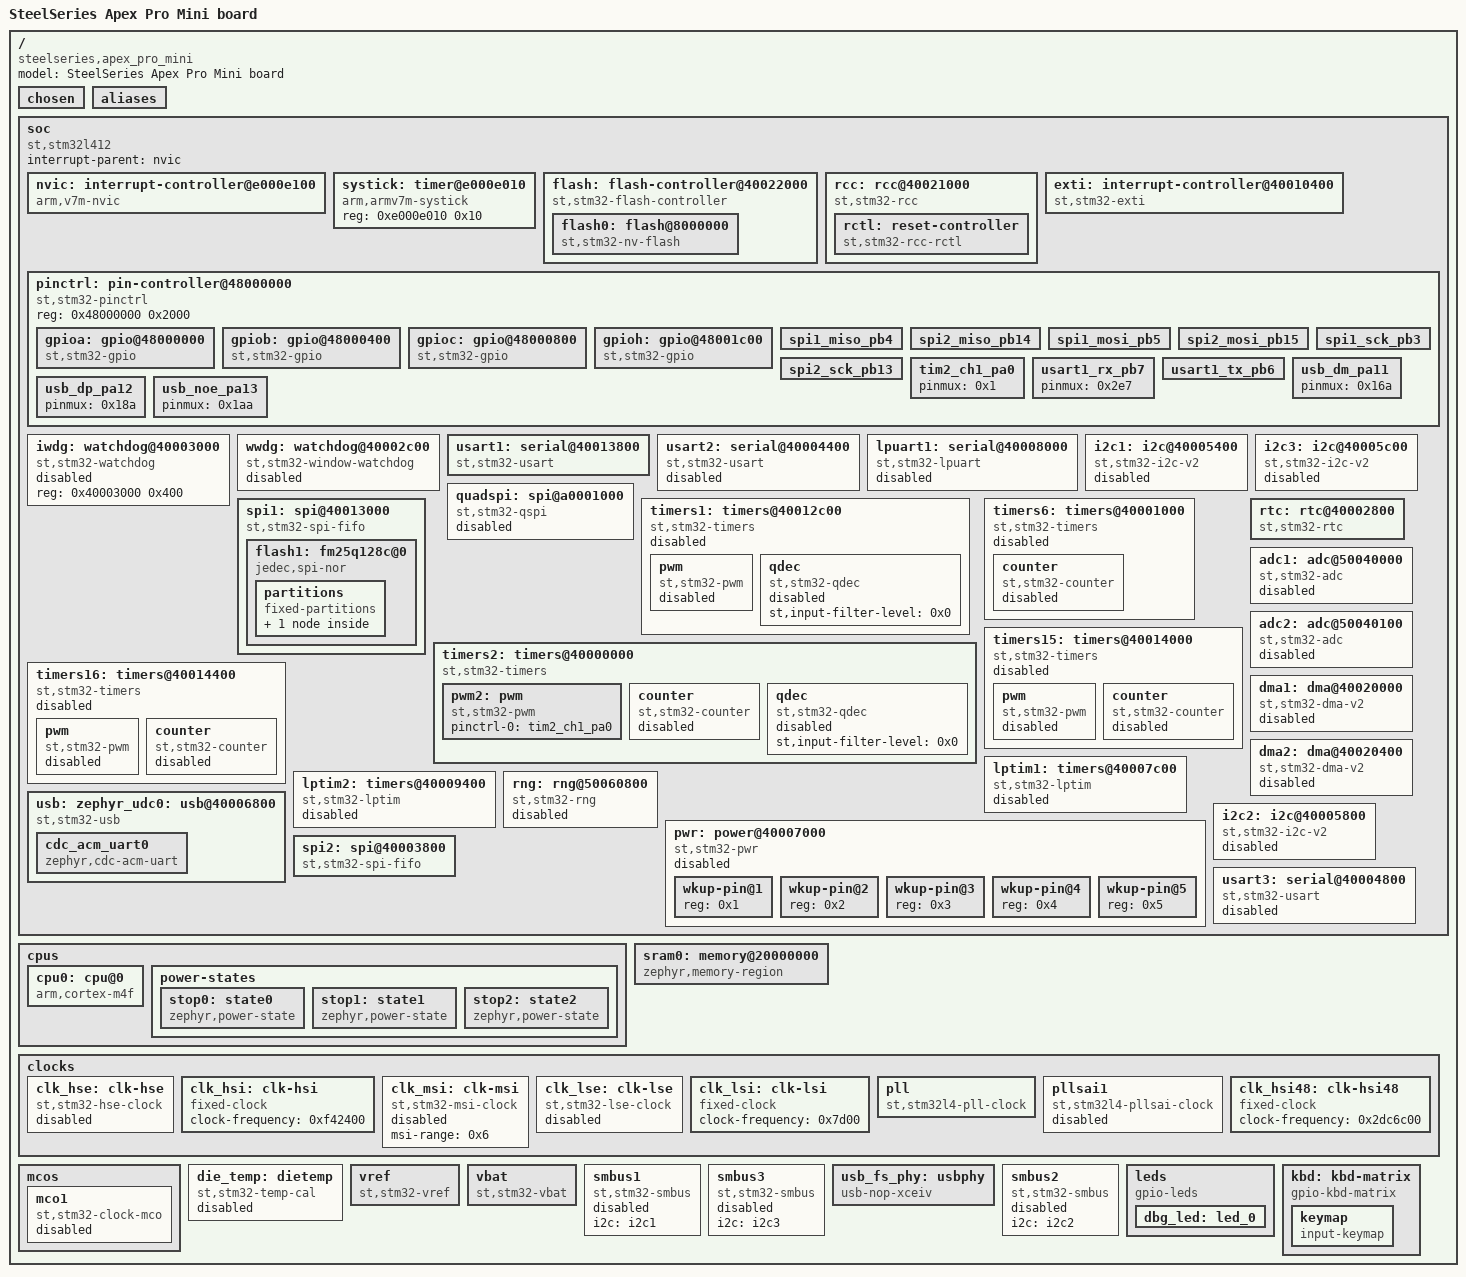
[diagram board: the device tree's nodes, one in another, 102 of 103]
/dts-v1/;

/* node '/' defined in zephyr/dts/common/skeleton.dtsi:9 */
/ {
	#address-cells = < 0x1 >;                  /* in zephyr/dts/common/skeleton.dtsi:10 */
	#size-cells = < 0x1 >;                     /* in zephyr/dts/common/skeleton.dtsi:11 */
	model = "SteelSeries Apex Pro Mini board"; /* in zephyr/boards/steelseries/apex_pro_mini/apex_pro_mini.dts:14 */
	compatible = "steelseries,apex_pro_mini",
	             "st,stm32l412";               /* in zephyr/boards/steelseries/apex_pro_mini/apex_pro_mini.dts:15 */

	/* node '/chosen' defined in zephyr/dts/common/skeleton.dtsi:13 */
	chosen {
		zephyr,entropy = &rng;              /* in zephyr/dts/arm/st/l4/stm32l4.dtsi:26 */
		zephyr,flash-controller = &flash;   /* in zephyr/dts/arm/st/l4/stm32l4.dtsi:27 */
		zephyr,console = &cdc_acm_uart0;    /* in zephyr/boards/steelseries/apex_pro_mini/apex_pro_mini.dts:18 */
		zephyr,shell-uart = &cdc_acm_uart0; /* in zephyr/boards/steelseries/apex_pro_mini/apex_pro_mini.dts:19 */
		zephyr,sram = &sram0;               /* in zephyr/boards/steelseries/apex_pro_mini/apex_pro_mini.dts:20 */
		zephyr,flash = &flash0;             /* in zephyr/boards/steelseries/apex_pro_mini/apex_pro_mini.dts:21 */
	};

	/* node '/aliases' defined in zephyr/dts/common/skeleton.dtsi:15 */
	aliases {
		led0 = &dbg_led;      /* in zephyr/boards/steelseries/apex_pro_mini/apex_pro_mini.dts:34 */
		volt-sensor0 = &vref; /* in zephyr/boards/steelseries/apex_pro_mini/apex_pro_mini.dts:35 */
		volt-sensor1 = &vbat; /* in zephyr/boards/steelseries/apex_pro_mini/apex_pro_mini.dts:36 */
	};

	/* node '/soc' defined in zephyr/dts/arm/armv7-m.dtsi:6 */
	soc {
		#address-cells = < 0x1 >;     /* in zephyr/dts/arm/armv7-m.dtsi:7 */
		#size-cells = < 0x1 >;        /* in zephyr/dts/arm/armv7-m.dtsi:8 */
		interrupt-parent = < &nvic >; /* in zephyr/dts/arm/armv7-m.dtsi:10 */
		ranges;                       /* in zephyr/dts/arm/armv7-m.dtsi:11 */
		compatible = "st,stm32l412",
		             "st,stm32l4",
		             "simple-bus";    /* in zephyr/dts/arm/st/l4/stm32l412.dtsi:20 */

		/* node '/soc/interrupt-controller@e000e100' defined in zephyr/dts/arm/armv7-m.dtsi:13 */
		nvic: interrupt-controller@e000e100 {
			#address-cells = < 0x1 >;            /* in zephyr/dts/arm/armv7-m.dtsi:14 */
			compatible = "arm,v7m-nvic";         /* in zephyr/dts/arm/armv7-m.dtsi:15 */
			reg = < 0xe000e100 0xc00 >;          /* in zephyr/dts/arm/armv7-m.dtsi:16 */
			interrupt-controller;                /* in zephyr/dts/arm/armv7-m.dtsi:17 */
			#interrupt-cells = < 0x2 >;          /* in zephyr/dts/arm/armv7-m.dtsi:18 */
			arm,num-irq-priority-bits = < 0x4 >; /* in zephyr/dts/arm/st/l4/stm32l4.dtsi:596 */
			phandle = < 0x1 >;                   /* in zephyr/dts/arm/armv7-m.dtsi:10 */
		};

		/* node '/soc/timer@e000e010' defined in zephyr/dts/arm/armv7-m.dtsi:21 */
		systick: timer@e000e010 {
			compatible = "arm,armv7m-systick"; /* in zephyr/dts/arm/armv7-m.dtsi:22 */
			reg = < 0xe000e010 0x10 >;         /* in zephyr/dts/arm/armv7-m.dtsi:23 */
		};

		/* node '/soc/flash-controller@40022000' defined in zephyr/dts/arm/st/l4/stm32l4.dtsi:127 */
		flash: flash-controller@40022000 {
			compatible = "st,stm32-flash-controller",
			             "st,stm32l4-flash-controller"; /* in zephyr/dts/arm/st/l4/stm32l4.dtsi:128 */
			reg = < 0x40022000 0x400 >;                 /* in zephyr/dts/arm/st/l4/stm32l4.dtsi:129 */
			interrupts = < 0x4 0x0 >;                   /* in zephyr/dts/arm/st/l4/stm32l4.dtsi:130 */
			clocks = < &rcc 0x48 0x100 >;               /* in zephyr/dts/arm/st/l4/stm32l4.dtsi:131 */
			#address-cells = < 0x1 >;                   /* in zephyr/dts/arm/st/l4/stm32l4.dtsi:133 */
			#size-cells = < 0x1 >;                      /* in zephyr/dts/arm/st/l4/stm32l4.dtsi:134 */

			/* node '/soc/flash-controller@40022000/flash@8000000' defined in zephyr/dts/arm/st/l4/stm32l4.dtsi:136 */
			flash0: flash@8000000 {
				compatible = "st,stm32-nv-flash",
				             "soc-nv-flash";      /* in zephyr/dts/arm/st/l4/stm32l4.dtsi:137 */
				write-block-size = < 0x8 >;       /* in zephyr/dts/arm/st/l4/stm32l4.dtsi:139 */
				erase-block-size = < 0x800 >;     /* in zephyr/dts/arm/st/l4/stm32l4.dtsi:140 */
				max-erase-time = < 0x19 >;        /* in zephyr/dts/arm/st/l4/stm32l4.dtsi:142 */
				reg = < 0x8000000 0x20000 >;      /* in zephyr/dts/arm/st/l4/stm32l412XB.dtsi:17 */
			};
		};

		/* node '/soc/rcc@40021000' defined in zephyr/dts/arm/st/l4/stm32l4.dtsi:146 */
		rcc: rcc@40021000 {
			compatible = "st,stm32-rcc";     /* in zephyr/dts/arm/st/l4/stm32l4.dtsi:147 */
			#clock-cells = < 0x2 >;          /* in zephyr/dts/arm/st/l4/stm32l4.dtsi:148 */
			reg = < 0x40021000 0x400 >;      /* in zephyr/dts/arm/st/l4/stm32l4.dtsi:149 */
			clocks = < &pll >;               /* in zephyr/boards/steelseries/apex_pro_mini/apex_pro_mini.dts:160 */
			clock-frequency = < 0x4c4b400 >; /* in zephyr/boards/steelseries/apex_pro_mini/apex_pro_mini.dts:161 */
			ahb-prescaler = < 0x1 >;         /* in zephyr/boards/steelseries/apex_pro_mini/apex_pro_mini.dts:162 */
			apb1-prescaler = < 0x1 >;        /* in zephyr/boards/steelseries/apex_pro_mini/apex_pro_mini.dts:163 */
			apb2-prescaler = < 0x1 >;        /* in zephyr/boards/steelseries/apex_pro_mini/apex_pro_mini.dts:164 */
			phandle = < 0x2 >;               /* in zephyr/dts/arm/st/l4/stm32l4.dtsi:131 */

			/* node '/soc/rcc@40021000/reset-controller' defined in zephyr/dts/arm/st/l4/stm32l4.dtsi:151 */
			rctl: reset-controller {
				compatible = "st,stm32-rcc-rctl"; /* in zephyr/dts/arm/st/l4/stm32l4.dtsi:152 */
				#reset-cells = < 0x1 >;           /* in zephyr/dts/arm/st/l4/stm32l4.dtsi:153 */
				phandle = < 0x4 >;                /* in zephyr/dts/arm/st/l4/stm32l4.dtsi:230 */
			};
		};

		/* node '/soc/interrupt-controller@40010400' defined in zephyr/dts/arm/st/l4/stm32l4.dtsi:157 */
		exti: interrupt-controller@40010400 {
			compatible = "st,stm32-exti";  /* in zephyr/dts/arm/st/l4/stm32l4.dtsi:158 */
			interrupt-controller;          /* in zephyr/dts/arm/st/l4/stm32l4.dtsi:159 */
			#interrupt-cells = < 0x1 >;    /* in zephyr/dts/arm/st/l4/stm32l4.dtsi:160 */
			#address-cells = < 0x0 >;      /* in zephyr/dts/arm/st/l4/stm32l4.dtsi:161 */
			reg = < 0x40010400 0x400 >;    /* in zephyr/dts/arm/st/l4/stm32l4.dtsi:162 */
			clocks = < &rcc 0x60 0x1 >;    /* in zephyr/dts/arm/st/l4/stm32l4.dtsi:163 */
			num-lines = < 0x40 >;          /* in zephyr/dts/arm/st/l4/stm32l4.dtsi:164 */
			interrupts = < 0x6 0x0 >,
			             < 0x7 0x0 >,
			             < 0x8 0x0 >,
			             < 0x9 0x0 >,
			             < 0xa 0x0 >,
			             < 0x17 0x0 >,
			             < 0x28 0x0 >;     /* in zephyr/dts/arm/st/l4/stm32l4.dtsi:165 */
			interrupt-names = "line0",
			                  "line1",
			                  "line2",
			                  "line3",
			                  "line4",
			                  "line5-9",
			                  "line10-15"; /* in zephyr/dts/arm/st/l4/stm32l4.dtsi:167 */
			line-ranges = < 0x0 0x1 >,
			              < 0x1 0x1 >,
			              < 0x2 0x1 >,
			              < 0x3 0x1 >,
			              < 0x4 0x1 >,
			              < 0x5 0x5 >,
			              < 0xa 0x6 >;     /* in zephyr/dts/arm/st/l4/stm32l4.dtsi:169 */
		};

		/* node '/soc/pin-controller@48000000' defined in zephyr/dts/arm/st/l4/stm32l4.dtsi:173 */
		pinctrl: pin-controller@48000000 {
			compatible = "st,stm32-pinctrl"; /* in zephyr/dts/arm/st/l4/stm32l4.dtsi:174 */
			#address-cells = < 0x1 >;        /* in zephyr/dts/arm/st/l4/stm32l4.dtsi:175 */
			#size-cells = < 0x1 >;           /* in zephyr/dts/arm/st/l4/stm32l4.dtsi:176 */
			reg = < 0x48000000 0x2000 >;     /* in zephyr/dts/arm/st/l4/stm32l4.dtsi:177 */

			/* node '/soc/pin-controller@48000000/gpio@48000000' defined in zephyr/dts/arm/st/l4/stm32l4.dtsi:179 */
			gpioa: gpio@48000000 {
				compatible = "st,stm32-gpio"; /* in zephyr/dts/arm/st/l4/stm32l4.dtsi:180 */
				gpio-controller;              /* in zephyr/dts/arm/st/l4/stm32l4.dtsi:181 */
				#gpio-cells = < 0x2 >;        /* in zephyr/dts/arm/st/l4/stm32l4.dtsi:182 */
				reg = < 0x48000000 0x400 >;   /* in zephyr/dts/arm/st/l4/stm32l4.dtsi:183 */
				clocks = < &rcc 0x4c 0x1 >;   /* in zephyr/dts/arm/st/l4/stm32l4.dtsi:184 */
				phandle = < 0xa >;            /* in zephyr/boards/steelseries/apex_pro_mini/apex_pro_mini.dts:177 */
			};

			/* node '/soc/pin-controller@48000000/gpio@48000400' defined in zephyr/dts/arm/st/l4/stm32l4.dtsi:187 */
			gpiob: gpio@48000400 {
				compatible = "st,stm32-gpio"; /* in zephyr/dts/arm/st/l4/stm32l4.dtsi:188 */
				gpio-controller;              /* in zephyr/dts/arm/st/l4/stm32l4.dtsi:189 */
				#gpio-cells = < 0x2 >;        /* in zephyr/dts/arm/st/l4/stm32l4.dtsi:190 */
				reg = < 0x48000400 0x400 >;   /* in zephyr/dts/arm/st/l4/stm32l4.dtsi:191 */
				clocks = < &rcc 0x4c 0x2 >;   /* in zephyr/dts/arm/st/l4/stm32l4.dtsi:192 */
				phandle = < 0x13 >;           /* in zephyr/boards/steelseries/apex_pro_mini/apex_pro_mini.dts:193 */
			};

			/* node '/soc/pin-controller@48000000/gpio@48000800' defined in zephyr/dts/arm/st/l4/stm32l4.dtsi:195 */
			gpioc: gpio@48000800 {
				compatible = "st,stm32-gpio"; /* in zephyr/dts/arm/st/l4/stm32l4.dtsi:196 */
				gpio-controller;              /* in zephyr/dts/arm/st/l4/stm32l4.dtsi:197 */
				#gpio-cells = < 0x2 >;        /* in zephyr/dts/arm/st/l4/stm32l4.dtsi:198 */
				reg = < 0x48000800 0x400 >;   /* in zephyr/dts/arm/st/l4/stm32l4.dtsi:199 */
				clocks = < &rcc 0x4c 0x4 >;   /* in zephyr/dts/arm/st/l4/stm32l4.dtsi:200 */
				phandle = < 0x1c >;           /* in zephyr/boards/steelseries/apex_pro_mini/apex_pro_mini.dts:28 */
			};

			/* node '/soc/pin-controller@48000000/gpio@48001c00' defined in zephyr/dts/arm/st/l4/stm32l4.dtsi:203 */
			gpioh: gpio@48001c00 {
				compatible = "st,stm32-gpio"; /* in zephyr/dts/arm/st/l4/stm32l4.dtsi:204 */
				gpio-controller;              /* in zephyr/dts/arm/st/l4/stm32l4.dtsi:205 */
				#gpio-cells = < 0x2 >;        /* in zephyr/dts/arm/st/l4/stm32l4.dtsi:206 */
				reg = < 0x48001c00 0x400 >;   /* in zephyr/dts/arm/st/l4/stm32l4.dtsi:207 */
				clocks = < &rcc 0x4c 0x80 >;  /* in zephyr/dts/arm/st/l4/stm32l4.dtsi:208 */
			};

			/* node '/soc/pin-controller@48000000/spi1_miso_pb4' defined in modules/hal/stm32/dts/st/l4/stm32l412rbtx-pinctrl.dtsi:613 */
			spi1_miso_pb4: spi1_miso_pb4 {
				pinmux = < 0x285 >; /* in modules/hal/stm32/dts/st/l4/stm32l412rbtx-pinctrl.dtsi:614 */
				bias-pull-down;     /* in modules/hal/stm32/dts/st/l4/stm32l412rbtx-pinctrl.dtsi:615 */
				phandle = < 0x8 >;  /* in zephyr/boards/steelseries/apex_pro_mini/apex_pro_mini.dts:175 */
			};

			/* node '/soc/pin-controller@48000000/spi2_miso_pb14' defined in modules/hal/stm32/dts/st/l4/stm32l412rbtx-pinctrl.dtsi:618 */
			spi2_miso_pb14: spi2_miso_pb14 {
				pinmux = < 0x3c5 >; /* in modules/hal/stm32/dts/st/l4/stm32l412rbtx-pinctrl.dtsi:619 */
				bias-pull-down;     /* in modules/hal/stm32/dts/st/l4/stm32l412rbtx-pinctrl.dtsi:620 */
				phandle = < 0x11 >; /* in zephyr/boards/steelseries/apex_pro_mini/apex_pro_mini.dts:191 */
			};

			/* node '/soc/pin-controller@48000000/spi1_mosi_pb5' defined in modules/hal/stm32/dts/st/l4/stm32l412rbtx-pinctrl.dtsi:640 */
			spi1_mosi_pb5: spi1_mosi_pb5 {
				pinmux = < 0x2a5 >; /* in modules/hal/stm32/dts/st/l4/stm32l412rbtx-pinctrl.dtsi:641 */
				bias-pull-down;     /* in modules/hal/stm32/dts/st/l4/stm32l412rbtx-pinctrl.dtsi:642 */
				phandle = < 0x9 >;  /* in zephyr/boards/steelseries/apex_pro_mini/apex_pro_mini.dts:175 */
			};

			/* node '/soc/pin-controller@48000000/spi2_mosi_pb15' defined in modules/hal/stm32/dts/st/l4/stm32l412rbtx-pinctrl.dtsi:645 */
			spi2_mosi_pb15: spi2_mosi_pb15 {
				pinmux = < 0x3e5 >; /* in modules/hal/stm32/dts/st/l4/stm32l412rbtx-pinctrl.dtsi:646 */
				bias-pull-down;     /* in modules/hal/stm32/dts/st/l4/stm32l412rbtx-pinctrl.dtsi:647 */
				phandle = < 0x12 >; /* in zephyr/boards/steelseries/apex_pro_mini/apex_pro_mini.dts:191 */
			};

			/* node '/soc/pin-controller@48000000/spi1_sck_pb3' defined in modules/hal/stm32/dts/st/l4/stm32l412rbtx-pinctrl.dtsi:696 */
			spi1_sck_pb3: spi1_sck_pb3 {
				pinmux = < 0x265 >;            /* in modules/hal/stm32/dts/st/l4/stm32l412rbtx-pinctrl.dtsi:697 */
				bias-pull-down;                /* in modules/hal/stm32/dts/st/l4/stm32l412rbtx-pinctrl.dtsi:698 */
				slew-rate = "very-high-speed"; /* in modules/hal/stm32/dts/st/l4/stm32l412rbtx-pinctrl.dtsi:699 */
				phandle = < 0x7 >;             /* in zephyr/boards/steelseries/apex_pro_mini/apex_pro_mini.dts:175 */
			};

			/* node '/soc/pin-controller@48000000/spi2_sck_pb13' defined in modules/hal/stm32/dts/st/l4/stm32l412rbtx-pinctrl.dtsi:708 */
			spi2_sck_pb13: spi2_sck_pb13 {
				pinmux = < 0x3a5 >;            /* in modules/hal/stm32/dts/st/l4/stm32l412rbtx-pinctrl.dtsi:709 */
				bias-pull-down;                /* in modules/hal/stm32/dts/st/l4/stm32l412rbtx-pinctrl.dtsi:710 */
				slew-rate = "very-high-speed"; /* in modules/hal/stm32/dts/st/l4/stm32l412rbtx-pinctrl.dtsi:711 */
				phandle = < 0x10 >;            /* in zephyr/boards/steelseries/apex_pro_mini/apex_pro_mini.dts:191 */
			};

			/* node '/soc/pin-controller@48000000/tim2_ch1_pa0' defined in modules/hal/stm32/dts/st/l4/stm32l412rbtx-pinctrl.dtsi:782 */
			tim2_ch1_pa0: tim2_ch1_pa0 {
				pinmux = < 0x1 >;  /* in modules/hal/stm32/dts/st/l4/stm32l412rbtx-pinctrl.dtsi:783 */
				phandle = < 0xb >; /* in zephyr/boards/steelseries/apex_pro_mini/apex_pro_mini.dts:202 */
			};

			/* node '/soc/pin-controller@48000000/usart1_rx_pb7' defined in modules/hal/stm32/dts/st/l4/stm32l412rbtx-pinctrl.dtsi:1069 */
			usart1_rx_pb7: usart1_rx_pb7 {
				pinmux = < 0x2e7 >; /* in modules/hal/stm32/dts/st/l4/stm32l412rbtx-pinctrl.dtsi:1070 */
				phandle = < 0x6 >;  /* in zephyr/boards/steelseries/apex_pro_mini/apex_pro_mini.dts:168 */
			};

			/* node '/soc/pin-controller@48000000/usart1_tx_pb6' defined in modules/hal/stm32/dts/st/l4/stm32l412rbtx-pinctrl.dtsi:1113 */
			usart1_tx_pb6: usart1_tx_pb6 {
				pinmux = < 0x2c7 >; /* in modules/hal/stm32/dts/st/l4/stm32l412rbtx-pinctrl.dtsi:1114 */
				bias-pull-up;       /* in modules/hal/stm32/dts/st/l4/stm32l412rbtx-pinctrl.dtsi:1115 */
				phandle = < 0x5 >;  /* in zephyr/boards/steelseries/apex_pro_mini/apex_pro_mini.dts:168 */
			};

			/* node '/soc/pin-controller@48000000/usb_dm_pa11' defined in modules/hal/stm32/dts/st/l4/stm32l412rbtx-pinctrl.dtsi:1150 */
			usb_dm_pa11: usb_dm_pa11 {
				pinmux = < 0x16a >; /* in modules/hal/stm32/dts/st/l4/stm32l412rbtx-pinctrl.dtsi:1151 */
				phandle = < 0xd >;  /* in zephyr/boards/steelseries/apex_pro_mini/apex_pro_mini.dts:232 */
			};

			/* node '/soc/pin-controller@48000000/usb_dp_pa12' defined in modules/hal/stm32/dts/st/l4/stm32l412rbtx-pinctrl.dtsi:1154 */
			usb_dp_pa12: usb_dp_pa12 {
				pinmux = < 0x18a >; /* in modules/hal/stm32/dts/st/l4/stm32l412rbtx-pinctrl.dtsi:1155 */
				phandle = < 0xe >;  /* in zephyr/boards/steelseries/apex_pro_mini/apex_pro_mini.dts:232 */
			};

			/* node '/soc/pin-controller@48000000/usb_noe_pa13' defined in modules/hal/stm32/dts/st/l4/stm32l412rbtx-pinctrl.dtsi:1158 */
			usb_noe_pa13: usb_noe_pa13 {
				pinmux = < 0x1aa >; /* in modules/hal/stm32/dts/st/l4/stm32l412rbtx-pinctrl.dtsi:1159 */
				phandle = < 0xf >;  /* in zephyr/boards/steelseries/apex_pro_mini/apex_pro_mini.dts:232 */
			};
		};

		/* node '/soc/watchdog@40003000' defined in zephyr/dts/arm/st/l4/stm32l4.dtsi:212 */
		iwdg: watchdog@40003000 {
			compatible = "st,stm32-watchdog"; /* in zephyr/dts/arm/st/l4/stm32l4.dtsi:213 */
			reg = < 0x40003000 0x400 >;       /* in zephyr/dts/arm/st/l4/stm32l4.dtsi:214 */
			status = "disabled";              /* in zephyr/dts/arm/st/l4/stm32l4.dtsi:215 */
		};

		/* node '/soc/watchdog@40002c00' defined in zephyr/dts/arm/st/l4/stm32l4.dtsi:218 */
		wwdg: watchdog@40002c00 {
			compatible = "st,stm32-window-watchdog"; /* in zephyr/dts/arm/st/l4/stm32l4.dtsi:219 */
			reg = < 0x40002c00 0x400 >;              /* in zephyr/dts/arm/st/l4/stm32l4.dtsi:220 */
			clocks = < &rcc 0x58 0x800 >;            /* in zephyr/dts/arm/st/l4/stm32l4.dtsi:221 */
			interrupts = < 0x0 0x7 >;                /* in zephyr/dts/arm/st/l4/stm32l4.dtsi:222 */
			status = "disabled";                     /* in zephyr/dts/arm/st/l4/stm32l4.dtsi:223 */
		};

		/* node '/soc/serial@40013800' defined in zephyr/dts/arm/st/l4/stm32l4.dtsi:226 */
		usart1: serial@40013800 {
			compatible = "st,stm32-usart",
			             "st,stm32-uart";                  /* in zephyr/dts/arm/st/l4/stm32l4.dtsi:227 */
			reg = < 0x40013800 0x400 >;                    /* in zephyr/dts/arm/st/l4/stm32l4.dtsi:228 */
			clocks = < &rcc 0x60 0x4000 >;                 /* in zephyr/dts/arm/st/l4/stm32l4.dtsi:229 */
			resets = < &rctl 0x80e >;                      /* in zephyr/dts/arm/st/l4/stm32l4.dtsi:230 */
			interrupts = < 0x25 0x0 >;                     /* in zephyr/dts/arm/st/l4/stm32l4.dtsi:231 */
			pinctrl-0 = < &usart1_tx_pb6 &usart1_rx_pb7 >; /* in zephyr/boards/steelseries/apex_pro_mini/apex_pro_mini.dts:168 */
			pinctrl-names = "default";                     /* in zephyr/boards/steelseries/apex_pro_mini/apex_pro_mini.dts:169 */
			current-speed = < 0x1c200 >;                   /* in zephyr/boards/steelseries/apex_pro_mini/apex_pro_mini.dts:170 */
			status = "okay";                               /* in zephyr/boards/steelseries/apex_pro_mini/apex_pro_mini.dts:171 */
		};

		/* node '/soc/serial@40004400' defined in zephyr/dts/arm/st/l4/stm32l4.dtsi:235 */
		usart2: serial@40004400 {
			compatible = "st,stm32-usart",
			             "st,stm32-uart";   /* in zephyr/dts/arm/st/l4/stm32l4.dtsi:236 */
			reg = < 0x40004400 0x400 >;     /* in zephyr/dts/arm/st/l4/stm32l4.dtsi:237 */
			clocks = < &rcc 0x58 0x20000 >; /* in zephyr/dts/arm/st/l4/stm32l4.dtsi:238 */
			resets = < &rctl 0x711 >;       /* in zephyr/dts/arm/st/l4/stm32l4.dtsi:239 */
			interrupts = < 0x26 0x0 >;      /* in zephyr/dts/arm/st/l4/stm32l4.dtsi:240 */
			status = "disabled";            /* in zephyr/dts/arm/st/l4/stm32l4.dtsi:241 */
		};

		/* node '/soc/serial@40008000' defined in zephyr/dts/arm/st/l4/stm32l4.dtsi:244 */
		lpuart1: serial@40008000 {
			compatible = "st,stm32-lpuart",
			             "st,stm32-uart";   /* in zephyr/dts/arm/st/l4/stm32l4.dtsi:245 */
			reg = < 0x40008000 0x400 >;     /* in zephyr/dts/arm/st/l4/stm32l4.dtsi:246 */
			clocks = < &rcc 0x5c 0x1 >;     /* in zephyr/dts/arm/st/l4/stm32l4.dtsi:247 */
			resets = < &rctl 0x780 >;       /* in zephyr/dts/arm/st/l4/stm32l4.dtsi:248 */
			interrupts = < 0x46 0x0 >;      /* in zephyr/dts/arm/st/l4/stm32l4.dtsi:249 */
			status = "disabled";            /* in zephyr/dts/arm/st/l4/stm32l4.dtsi:250 */
		};

		/* node '/soc/i2c@40005400' defined in zephyr/dts/arm/st/l4/stm32l4.dtsi:253 */
		i2c1: i2c@40005400 {
			compatible = "st,stm32-i2c-v2";  /* in zephyr/dts/arm/st/l4/stm32l4.dtsi:254 */
			clock-frequency = < 0x186a0 >;   /* in zephyr/dts/arm/st/l4/stm32l4.dtsi:255 */
			#address-cells = < 0x1 >;        /* in zephyr/dts/arm/st/l4/stm32l4.dtsi:256 */
			#size-cells = < 0x0 >;           /* in zephyr/dts/arm/st/l4/stm32l4.dtsi:257 */
			reg = < 0x40005400 0x400 >;      /* in zephyr/dts/arm/st/l4/stm32l4.dtsi:258 */
			clocks = < &rcc 0x58 0x200000 >; /* in zephyr/dts/arm/st/l4/stm32l4.dtsi:259 */
			interrupts = < 0x1f 0x0 >,
			             < 0x20 0x0 >;       /* in zephyr/dts/arm/st/l4/stm32l4.dtsi:260 */
			interrupt-names = "event",
			                  "error";       /* in zephyr/dts/arm/st/l4/stm32l4.dtsi:261 */
			status = "disabled";             /* in zephyr/dts/arm/st/l4/stm32l4.dtsi:262 */
			phandle = < 0x19 >;              /* in zephyr/dts/arm/st/l4/stm32l4.dtsi:582 */
		};

		/* node '/soc/i2c@40005c00' defined in zephyr/dts/arm/st/l4/stm32l4.dtsi:265 */
		i2c3: i2c@40005c00 {
			compatible = "st,stm32-i2c-v2";  /* in zephyr/dts/arm/st/l4/stm32l4.dtsi:266 */
			clock-frequency = < 0x186a0 >;   /* in zephyr/dts/arm/st/l4/stm32l4.dtsi:267 */
			#address-cells = < 0x1 >;        /* in zephyr/dts/arm/st/l4/stm32l4.dtsi:268 */
			#size-cells = < 0x0 >;           /* in zephyr/dts/arm/st/l4/stm32l4.dtsi:269 */
			reg = < 0x40005c00 0x400 >;      /* in zephyr/dts/arm/st/l4/stm32l4.dtsi:270 */
			clocks = < &rcc 0x58 0x800000 >; /* in zephyr/dts/arm/st/l4/stm32l4.dtsi:271 */
			interrupts = < 0x48 0x0 >,
			             < 0x49 0x0 >;       /* in zephyr/dts/arm/st/l4/stm32l4.dtsi:272 */
			interrupt-names = "event",
			                  "error";       /* in zephyr/dts/arm/st/l4/stm32l4.dtsi:273 */
			status = "disabled";             /* in zephyr/dts/arm/st/l4/stm32l4.dtsi:274 */
			phandle = < 0x1a >;              /* in zephyr/dts/arm/st/l4/stm32l4.dtsi:590 */
		};

		/* node '/soc/spi@a0001000' defined in zephyr/dts/arm/st/l4/stm32l4.dtsi:277 */
		quadspi: spi@a0001000 {
			compatible = "st,stm32-qspi";    /* in zephyr/dts/arm/st/l4/stm32l4.dtsi:278 */
			#address-cells = < 0x1 >;        /* in zephyr/dts/arm/st/l4/stm32l4.dtsi:279 */
			#size-cells = < 0x0 >;           /* in zephyr/dts/arm/st/l4/stm32l4.dtsi:280 */
			reg = < 0xa0001000 0x400 >,
			      < 0x90000000 0x10000000 >; /* in zephyr/dts/arm/st/l4/stm32l4.dtsi:281 */
			interrupts = < 0x47 0x0 >;       /* in zephyr/dts/arm/st/l4/stm32l4.dtsi:282 */
			clocks = < &rcc 0x50 0x100 >;    /* in zephyr/dts/arm/st/l4/stm32l4.dtsi:283 */
			status = "disabled";             /* in zephyr/dts/arm/st/l4/stm32l4.dtsi:284 */
		};

		/* node '/soc/spi@40013000' defined in zephyr/dts/arm/st/l4/stm32l4.dtsi:287 */
		spi1: spi@40013000 {
			compatible = "st,stm32-spi-fifo",
			             "st,stm32-spi";                                 /* in zephyr/dts/arm/st/l4/stm32l4.dtsi:288 */
			#address-cells = < 0x1 >;                                    /* in zephyr/dts/arm/st/l4/stm32l4.dtsi:289 */
			#size-cells = < 0x0 >;                                       /* in zephyr/dts/arm/st/l4/stm32l4.dtsi:290 */
			reg = < 0x40013000 0x400 >;                                  /* in zephyr/dts/arm/st/l4/stm32l4.dtsi:291 */
			interrupts = < 0x23 0x5 >;                                   /* in zephyr/dts/arm/st/l4/stm32l4.dtsi:292 */
			clocks = < &rcc 0x60 0x1000 >;                               /* in zephyr/dts/arm/st/l4/stm32l4.dtsi:293 */
			pinctrl-0 = < &spi1_sck_pb3 &spi1_miso_pb4 &spi1_mosi_pb5 >; /* in zephyr/boards/steelseries/apex_pro_mini/apex_pro_mini.dts:175 */
			pinctrl-names = "default";                                   /* in zephyr/boards/steelseries/apex_pro_mini/apex_pro_mini.dts:176 */
			cs-gpios = < &gpioa 0xf 0x11 >;                              /* in zephyr/boards/steelseries/apex_pro_mini/apex_pro_mini.dts:177 */
			status = "okay";                                             /* in zephyr/boards/steelseries/apex_pro_mini/apex_pro_mini.dts:178 */

			/* node '/soc/spi@40013000/fm25q128c@0' defined in zephyr/boards/steelseries/apex_pro_mini/apex_pro_mini.dts:180 */
			flash1: fm25q128c@0 {
				compatible = "jedec,spi-nor";     /* in zephyr/boards/steelseries/apex_pro_mini/apex_pro_mini.dts:181 */
				reg = < 0x0 >;                    /* in zephyr/boards/steelseries/apex_pro_mini/apex_pro_mini.dts:182 */
				spi-max-frequency = < 0x989680 >; /* in zephyr/boards/steelseries/apex_pro_mini/apex_pro_mini.dts:183 */
				size = < 0x1000000 >;             /* in zephyr/boards/steelseries/apex_pro_mini/apex_pro_mini.dts:184 */
				jedec-id = [ A1 40 14 ];          /* in zephyr/boards/steelseries/apex_pro_mini/apex_pro_mini.dts:185 */
				has-dpd;                          /* in zephyr/boards/steelseries/apex_pro_mini/apex_pro_mini.dts:186 */

				/* node '/soc/spi@40013000/fm25q128c@0/partitions' defined in zephyr/boards/steelseries/apex_pro_mini/apex_pro_mini.dts:214 */
				partitions {
					compatible = "fixed-partitions"; /* in zephyr/boards/steelseries/apex_pro_mini/apex_pro_mini.dts:215 */
					#address-cells = < 0x1 >;        /* in zephyr/boards/steelseries/apex_pro_mini/apex_pro_mini.dts:216 */
					#size-cells = < 0x1 >;           /* in zephyr/boards/steelseries/apex_pro_mini/apex_pro_mini.dts:217 */

					/* node '/soc/spi@40013000/fm25q128c@0/partitions/partition@0' defined in zephyr/boards/steelseries/apex_pro_mini/apex_pro_mini.dts:219 */
					storage_partition: partition@0 {
						label = "storage";       /* in zephyr/boards/steelseries/apex_pro_mini/apex_pro_mini.dts:220 */
						reg = < 0x0 0x1000000 >; /* in zephyr/boards/steelseries/apex_pro_mini/apex_pro_mini.dts:221 */
					};
				};
			};
		};

		/* node '/soc/timers@40012c00' defined in zephyr/dts/arm/st/l4/stm32l4.dtsi:297 */
		timers1: timers@40012c00 {
			compatible = "st,stm32-timers"; /* in zephyr/dts/arm/st/l4/stm32l4.dtsi:298 */
			reg = < 0x40012c00 0x400 >;     /* in zephyr/dts/arm/st/l4/stm32l4.dtsi:299 */
			clocks = < &rcc 0x60 0x800 >,
			         < &rcc 0x9 0xff >;     /* in zephyr/dts/arm/st/l4/stm32l4.dtsi:300 */
			resets = < &rctl 0x80b >;       /* in zephyr/dts/arm/st/l4/stm32l4.dtsi:302 */
			interrupts = < 0x18 0x0 >,
			             < 0x19 0x0 >,
			             < 0x1a 0x0 >,
			             < 0x1b 0x0 >;      /* in zephyr/dts/arm/st/l4/stm32l4.dtsi:303 */
			interrupt-names = "brk",
			                  "up",
			                  "trgcom",
			                  "cc";         /* in zephyr/dts/arm/st/l4/stm32l4.dtsi:304 */
			st,prescaler = < 0x0 >;         /* in zephyr/dts/arm/st/l4/stm32l4.dtsi:305 */
			status = "disabled";            /* in zephyr/dts/arm/st/l4/stm32l4.dtsi:306 */

			/* node '/soc/timers@40012c00/pwm' defined in zephyr/dts/arm/st/l4/stm32l4.dtsi:308 */
			pwm {
				compatible = "st,stm32-pwm"; /* in zephyr/dts/arm/st/l4/stm32l4.dtsi:309 */
				status = "disabled";         /* in zephyr/dts/arm/st/l4/stm32l4.dtsi:310 */
				#pwm-cells = < 0x3 >;        /* in zephyr/dts/arm/st/l4/stm32l4.dtsi:311 */
			};

			/* node '/soc/timers@40012c00/qdec' defined in zephyr/dts/arm/st/l4/stm32l4.dtsi:314 */
			qdec {
				compatible = "st,stm32-qdec";    /* in zephyr/dts/arm/st/l4/stm32l4.dtsi:315 */
				st,input-filter-level = < 0x0 >; /* in zephyr/dts/arm/st/l4/stm32l4.dtsi:316 */
				status = "disabled";             /* in zephyr/dts/arm/st/l4/stm32l4.dtsi:317 */
			};
		};

		/* node '/soc/timers@40000000' defined in zephyr/dts/arm/st/l4/stm32l4.dtsi:321 */
		timers2: timers@40000000 {
			compatible = "st,stm32-timers"; /* in zephyr/dts/arm/st/l4/stm32l4.dtsi:322 */
			reg = < 0x40000000 0x400 >;     /* in zephyr/dts/arm/st/l4/stm32l4.dtsi:323 */
			clocks = < &rcc 0x58 0x1 >,
			         < &rcc 0x8 0xff >;     /* in zephyr/dts/arm/st/l4/stm32l4.dtsi:324 */
			resets = < &rctl 0x700 >;       /* in zephyr/dts/arm/st/l4/stm32l4.dtsi:326 */
			interrupts = < 0x1c 0x0 >;      /* in zephyr/dts/arm/st/l4/stm32l4.dtsi:327 */
			interrupt-names = "global";     /* in zephyr/dts/arm/st/l4/stm32l4.dtsi:328 */
			st,prescaler = < 0x0 >;         /* in zephyr/dts/arm/st/l4/stm32l4.dtsi:329 */
			status = "okay";                /* in zephyr/boards/steelseries/apex_pro_mini/apex_pro_mini.dts:198 */

			/* node '/soc/timers@40000000/pwm' defined in zephyr/dts/arm/st/l4/stm32l4.dtsi:332 */
			pwm2: pwm {
				compatible = "st,stm32-pwm";   /* in zephyr/dts/arm/st/l4/stm32l4.dtsi:333 */
				#pwm-cells = < 0x3 >;          /* in zephyr/dts/arm/st/l4/stm32l4.dtsi:335 */
				status = "okay";               /* in zephyr/boards/steelseries/apex_pro_mini/apex_pro_mini.dts:201 */
				pinctrl-0 = < &tim2_ch1_pa0 >; /* in zephyr/boards/steelseries/apex_pro_mini/apex_pro_mini.dts:202 */
				pinctrl-names = "default";     /* in zephyr/boards/steelseries/apex_pro_mini/apex_pro_mini.dts:203 */
			};

			/* node '/soc/timers@40000000/counter' defined in zephyr/dts/arm/st/l4/stm32l4.dtsi:338 */
			counter {
				compatible = "st,stm32-counter"; /* in zephyr/dts/arm/st/l4/stm32l4.dtsi:339 */
				status = "disabled";             /* in zephyr/dts/arm/st/l4/stm32l4.dtsi:340 */
			};

			/* node '/soc/timers@40000000/qdec' defined in zephyr/dts/arm/st/l4/stm32l4.dtsi:343 */
			qdec {
				compatible = "st,stm32-qdec";    /* in zephyr/dts/arm/st/l4/stm32l4.dtsi:344 */
				st,input-filter-level = < 0x0 >; /* in zephyr/dts/arm/st/l4/stm32l4.dtsi:345 */
				status = "disabled";             /* in zephyr/dts/arm/st/l4/stm32l4.dtsi:346 */
			};
		};

		/* node '/soc/timers@40001000' defined in zephyr/dts/arm/st/l4/stm32l4.dtsi:350 */
		timers6: timers@40001000 {
			compatible = "st,stm32-timers"; /* in zephyr/dts/arm/st/l4/stm32l4.dtsi:351 */
			reg = < 0x40001000 0x400 >;     /* in zephyr/dts/arm/st/l4/stm32l4.dtsi:352 */
			clocks = < &rcc 0x58 0x10 >,
			         < &rcc 0x8 0xff >;     /* in zephyr/dts/arm/st/l4/stm32l4.dtsi:353 */
			resets = < &rctl 0x704 >;       /* in zephyr/dts/arm/st/l4/stm32l4.dtsi:355 */
			interrupts = < 0x36 0x0 >;      /* in zephyr/dts/arm/st/l4/stm32l4.dtsi:356 */
			interrupt-names = "global";     /* in zephyr/dts/arm/st/l4/stm32l4.dtsi:357 */
			st,prescaler = < 0x0 >;         /* in zephyr/dts/arm/st/l4/stm32l4.dtsi:358 */
			status = "disabled";            /* in zephyr/dts/arm/st/l4/stm32l4.dtsi:359 */

			/* node '/soc/timers@40001000/counter' defined in zephyr/dts/arm/st/l4/stm32l4.dtsi:361 */
			counter {
				compatible = "st,stm32-counter"; /* in zephyr/dts/arm/st/l4/stm32l4.dtsi:362 */
				status = "disabled";             /* in zephyr/dts/arm/st/l4/stm32l4.dtsi:363 */
			};
		};

		/* node '/soc/timers@40014000' defined in zephyr/dts/arm/st/l4/stm32l4.dtsi:367 */
		timers15: timers@40014000 {
			compatible = "st,stm32-timers"; /* in zephyr/dts/arm/st/l4/stm32l4.dtsi:368 */
			reg = < 0x40014000 0x400 >;     /* in zephyr/dts/arm/st/l4/stm32l4.dtsi:369 */
			clocks = < &rcc 0x60 0x10000 >,
			         < &rcc 0x9 0xff >;     /* in zephyr/dts/arm/st/l4/stm32l4.dtsi:370 */
			resets = < &rctl 0x810 >;       /* in zephyr/dts/arm/st/l4/stm32l4.dtsi:372 */
			interrupts = < 0x18 0x0 >;      /* in zephyr/dts/arm/st/l4/stm32l4.dtsi:373 */
			interrupt-names = "global";     /* in zephyr/dts/arm/st/l4/stm32l4.dtsi:374 */
			st,prescaler = < 0x0 >;         /* in zephyr/dts/arm/st/l4/stm32l4.dtsi:375 */
			status = "disabled";            /* in zephyr/dts/arm/st/l4/stm32l4.dtsi:376 */

			/* node '/soc/timers@40014000/pwm' defined in zephyr/dts/arm/st/l4/stm32l4.dtsi:378 */
			pwm {
				compatible = "st,stm32-pwm"; /* in zephyr/dts/arm/st/l4/stm32l4.dtsi:379 */
				status = "disabled";         /* in zephyr/dts/arm/st/l4/stm32l4.dtsi:380 */
				#pwm-cells = < 0x3 >;        /* in zephyr/dts/arm/st/l4/stm32l4.dtsi:381 */
			};

			/* node '/soc/timers@40014000/counter' defined in zephyr/dts/arm/st/l4/stm32l4.dtsi:384 */
			counter {
				compatible = "st,stm32-counter"; /* in zephyr/dts/arm/st/l4/stm32l4.dtsi:385 */
				status = "disabled";             /* in zephyr/dts/arm/st/l4/stm32l4.dtsi:386 */
			};
		};

		/* node '/soc/timers@40014400' defined in zephyr/dts/arm/st/l4/stm32l4.dtsi:390 */
		timers16: timers@40014400 {
			compatible = "st,stm32-timers"; /* in zephyr/dts/arm/st/l4/stm32l4.dtsi:391 */
			reg = < 0x40014400 0x400 >;     /* in zephyr/dts/arm/st/l4/stm32l4.dtsi:392 */
			clocks = < &rcc 0x60 0x20000 >,
			         < &rcc 0x9 0xff >;     /* in zephyr/dts/arm/st/l4/stm32l4.dtsi:393 */
			resets = < &rctl 0x811 >;       /* in zephyr/dts/arm/st/l4/stm32l4.dtsi:395 */
			interrupts = < 0x19 0x0 >;      /* in zephyr/dts/arm/st/l4/stm32l4.dtsi:396 */
			interrupt-names = "global";     /* in zephyr/dts/arm/st/l4/stm32l4.dtsi:397 */
			st,prescaler = < 0x0 >;         /* in zephyr/dts/arm/st/l4/stm32l4.dtsi:398 */
			status = "disabled";            /* in zephyr/dts/arm/st/l4/stm32l4.dtsi:399 */

			/* node '/soc/timers@40014400/pwm' defined in zephyr/dts/arm/st/l4/stm32l4.dtsi:401 */
			pwm {
				compatible = "st,stm32-pwm"; /* in zephyr/dts/arm/st/l4/stm32l4.dtsi:402 */
				status = "disabled";         /* in zephyr/dts/arm/st/l4/stm32l4.dtsi:403 */
				#pwm-cells = < 0x3 >;        /* in zephyr/dts/arm/st/l4/stm32l4.dtsi:404 */
			};

			/* node '/soc/timers@40014400/counter' defined in zephyr/dts/arm/st/l4/stm32l4.dtsi:407 */
			counter {
				compatible = "st,stm32-counter"; /* in zephyr/dts/arm/st/l4/stm32l4.dtsi:408 */
				status = "disabled";             /* in zephyr/dts/arm/st/l4/stm32l4.dtsi:409 */
			};
		};

		/* node '/soc/rtc@40002800' defined in zephyr/dts/arm/st/l4/stm32l4.dtsi:413 */
		rtc: rtc@40002800 {
			compatible = "st,stm32-rtc";       /* in zephyr/dts/arm/st/l4/stm32l4.dtsi:414 */
			reg = < 0x40002800 0x400 >;        /* in zephyr/dts/arm/st/l4/stm32l4.dtsi:415 */
			interrupts = < 0x29 0x0 >;         /* in zephyr/dts/arm/st/l4/stm32l4.dtsi:416 */
			prescaler = < 0x8000 >;            /* in zephyr/dts/arm/st/l4/stm32l4.dtsi:418 */
			alarms-count = < 0x2 >;            /* in zephyr/dts/arm/st/l4/stm32l4.dtsi:419 */
			alrm-exti-line = < 0x12 >;         /* in zephyr/dts/arm/st/l4/stm32l4.dtsi:420 */
			clocks = < &rcc 0x58 0x10000000 >,
			         < &rcc 0x3 0x2280090 >;   /* in zephyr/boards/steelseries/apex_pro_mini/apex_pro_mini.dts:208 */
			status = "okay";                   /* in zephyr/boards/steelseries/apex_pro_mini/apex_pro_mini.dts:210 */
		};

		/* node '/soc/adc@50040000' defined in zephyr/dts/arm/st/l4/stm32l4.dtsi:424 */
		adc1: adc@50040000 {
			compatible = "st,stm32-adc";                                /* in zephyr/dts/arm/st/l4/stm32l4.dtsi:425 */
			reg = < 0x50040000 0x100 >;                                 /* in zephyr/dts/arm/st/l4/stm32l4.dtsi:426 */
			clocks = < &rcc 0x4c 0x2000 >;                              /* in zephyr/dts/arm/st/l4/stm32l4.dtsi:427 */
			clock-names = "adcx";                                       /* in zephyr/dts/arm/st/l4/stm32l4.dtsi:428 */
			interrupts = < 0x12 0x0 >;                                  /* in zephyr/dts/arm/st/l4/stm32l4.dtsi:429 */
			#io-channel-cells = < 0x1 >;                                /* in zephyr/dts/arm/st/l4/stm32l4.dtsi:430 */
			resolutions = < 0x60630c 0x51630c 0x42630c 0x33630c >;      /* in zephyr/dts/arm/st/l4/stm32l4.dtsi:431 */
			sampling-times = < 0x3 0x7 0xd 0x19 0x30 0x5d 0xf8 0x281 >; /* in zephyr/dts/arm/st/l4/stm32l4.dtsi:435 */
			st,adc-sequencer = "programmable";                          /* in zephyr/dts/arm/st/l4/stm32l4.dtsi:436 */
			st,adc-oversampler = "minimal";                             /* in zephyr/dts/arm/st/l4/stm32l4.dtsi:437 */
			st,adc-internal-regulator = "startup-sw-delay";             /* in zephyr/dts/arm/st/l4/stm32l4.dtsi:438 */
			st,adc-has-deep-powerdown;                                  /* in zephyr/dts/arm/st/l4/stm32l4.dtsi:439 */
			st,adc-has-differential-support;                            /* in zephyr/dts/arm/st/l4/stm32l4.dtsi:440 */
			status = "disabled";                                        /* in zephyr/dts/arm/st/l4/stm32l4.dtsi:441 */
			phandle = < 0x18 >;                                         /* in zephyr/dts/arm/st/l4/stm32l4.dtsi:559 */
		};

		/* node '/soc/adc@50040100' defined in zephyr/dts/arm/st/l4/stm32l4.dtsi:444 */
		adc2: adc@50040100 {
			compatible = "st,stm32-adc";                                /* in zephyr/dts/arm/st/l4/stm32l4.dtsi:445 */
			reg = < 0x50040100 0x100 >;                                 /* in zephyr/dts/arm/st/l4/stm32l4.dtsi:446 */
			clocks = < &rcc 0x4c 0x2000 >;                              /* in zephyr/dts/arm/st/l4/stm32l4.dtsi:447 */
			clock-names = "adcx";                                       /* in zephyr/dts/arm/st/l4/stm32l4.dtsi:448 */
			interrupts = < 0x12 0x0 >;                                  /* in zephyr/dts/arm/st/l4/stm32l4.dtsi:449 */
			#io-channel-cells = < 0x1 >;                                /* in zephyr/dts/arm/st/l4/stm32l4.dtsi:450 */
			resolutions = < 0x60630c 0x51630c 0x42630c 0x33630c >;      /* in zephyr/dts/arm/st/l4/stm32l4.dtsi:451 */
			sampling-times = < 0x3 0x7 0xd 0x19 0x30 0x5d 0xf8 0x281 >; /* in zephyr/dts/arm/st/l4/stm32l4.dtsi:455 */
			st,adc-sequencer = "programmable";                          /* in zephyr/dts/arm/st/l4/stm32l4.dtsi:456 */
			st,adc-oversampler = "minimal";                             /* in zephyr/dts/arm/st/l4/stm32l4.dtsi:457 */
			st,adc-internal-regulator = "startup-sw-delay";             /* in zephyr/dts/arm/st/l4/stm32l4.dtsi:458 */
			st,adc-has-deep-powerdown;                                  /* in zephyr/dts/arm/st/l4/stm32l4.dtsi:459 */
			st,adc-has-differential-support;                            /* in zephyr/dts/arm/st/l4/stm32l4.dtsi:460 */
			status = "disabled";                                        /* in zephyr/dts/arm/st/l4/stm32l4.dtsi:461 */
		};

		/* node '/soc/dma@40020000' defined in zephyr/dts/arm/st/l4/stm32l4.dtsi:464 */
		dma1: dma@40020000 {
			compatible = "st,stm32-dma-v2";                                             /* in zephyr/dts/arm/st/l4/stm32l4.dtsi:465 */
			#dma-cells = < 0x3 >;                                                       /* in zephyr/dts/arm/st/l4/stm32l4.dtsi:466 */
			reg = < 0x40020000 0x400 >;                                                 /* in zephyr/dts/arm/st/l4/stm32l4.dtsi:467 */
			interrupts = < 0xb 0x0 0xc 0x0 0xd 0x0 0xe 0x0 0xf 0x0 0x10 0x0 0x11 0x0 >; /* in zephyr/dts/arm/st/l4/stm32l4.dtsi:468 */
			clocks = < &rcc 0x48 0x1 >;                                                 /* in zephyr/dts/arm/st/l4/stm32l4.dtsi:469 */
			dma-requests = < 0x7 >;                                                     /* in zephyr/dts/arm/st/l4/stm32l4.dtsi:470 */
			status = "disabled";                                                        /* in zephyr/dts/arm/st/l4/stm32l4.dtsi:471 */
		};

		/* node '/soc/dma@40020400' defined in zephyr/dts/arm/st/l4/stm32l4.dtsi:474 */
		dma2: dma@40020400 {
			compatible = "st,stm32-dma-v2";                                                  /* in zephyr/dts/arm/st/l4/stm32l4.dtsi:475 */
			#dma-cells = < 0x3 >;                                                            /* in zephyr/dts/arm/st/l4/stm32l4.dtsi:476 */
			reg = < 0x40020400 0x400 >;                                                      /* in zephyr/dts/arm/st/l4/stm32l4.dtsi:477 */
			interrupts = < 0x38 0x0 0x39 0x0 0x3a 0x0 0x3b 0x0 0x3c 0x0 0x44 0x0 0x45 0x0 >; /* in zephyr/dts/arm/st/l4/stm32l4.dtsi:478 */
			clocks = < &rcc 0x48 0x2 >;                                                      /* in zephyr/dts/arm/st/l4/stm32l4.dtsi:479 */
			dma-requests = < 0x7 >;                                                          /* in zephyr/dts/arm/st/l4/stm32l4.dtsi:480 */
			status = "disabled";                                                             /* in zephyr/dts/arm/st/l4/stm32l4.dtsi:481 */
		};

		/* node '/soc/timers@40007c00' defined in zephyr/dts/arm/st/l4/stm32l4.dtsi:484 */
		lptim1: timers@40007c00 {
			compatible = "st,stm32-lptim";     /* in zephyr/dts/arm/st/l4/stm32l4.dtsi:485 */
			clocks = < &rcc 0x58 0x80000000 >; /* in zephyr/dts/arm/st/l4/stm32l4.dtsi:486 */
			#address-cells = < 0x1 >;          /* in zephyr/dts/arm/st/l4/stm32l4.dtsi:487 */
			#size-cells = < 0x0 >;             /* in zephyr/dts/arm/st/l4/stm32l4.dtsi:488 */
			reg = < 0x40007c00 0x400 >;        /* in zephyr/dts/arm/st/l4/stm32l4.dtsi:489 */
			interrupts = < 0x41 0x1 >;         /* in zephyr/dts/arm/st/l4/stm32l4.dtsi:490 */
			interrupt-names = "wakeup";        /* in zephyr/dts/arm/st/l4/stm32l4.dtsi:491 */
			status = "disabled";               /* in zephyr/dts/arm/st/l4/stm32l4.dtsi:492 */
		};

		/* node '/soc/timers@40009400' defined in zephyr/dts/arm/st/l4/stm32l4.dtsi:495 */
		lptim2: timers@40009400 {
			compatible = "st,stm32-lptim"; /* in zephyr/dts/arm/st/l4/stm32l4.dtsi:496 */
			#address-cells = < 0x1 >;      /* in zephyr/dts/arm/st/l4/stm32l4.dtsi:497 */
			#size-cells = < 0x0 >;         /* in zephyr/dts/arm/st/l4/stm32l4.dtsi:498 */
			reg = < 0x40009400 0x400 >;    /* in zephyr/dts/arm/st/l4/stm32l4.dtsi:499 */
			clocks = < &rcc 0x5c 0x20 >;   /* in zephyr/dts/arm/st/l4/stm32l4.dtsi:500 */
			interrupts = < 0x42 0x1 >;     /* in zephyr/dts/arm/st/l4/stm32l4.dtsi:501 */
			interrupt-names = "wakeup";    /* in zephyr/dts/arm/st/l4/stm32l4.dtsi:502 */
			status = "disabled";           /* in zephyr/dts/arm/st/l4/stm32l4.dtsi:503 */
		};

		/* node '/soc/rng@50060800' defined in zephyr/dts/arm/st/l4/stm32l4.dtsi:506 */
		rng: rng@50060800 {
			compatible = "st,stm32-rng";    /* in zephyr/dts/arm/st/l4/stm32l4.dtsi:507 */
			reg = < 0x50060800 0x400 >;     /* in zephyr/dts/arm/st/l4/stm32l4.dtsi:508 */
			interrupts = < 0x50 0x0 >;      /* in zephyr/dts/arm/st/l4/stm32l4.dtsi:509 */
			status = "disabled";            /* in zephyr/dts/arm/st/l4/stm32l4.dtsi:515 */
			clocks = < &rcc 0x4c 0x40000 >,
			         < &rcc 0x5 0x3a0088 >; /* in zephyr/dts/arm/st/l4/stm32l412.dtsi:23 */
		};

		/* node '/soc/power@40007000' defined in zephyr/dts/arm/st/l4/stm32l4.dtsi:518 */
		pwr: power@40007000 {
			compatible = "st,stm32-pwr"; /* in zephyr/dts/arm/st/l4/stm32l4.dtsi:519 */
			reg = < 0x40007000 0x400 >;  /* in zephyr/dts/arm/st/l4/stm32l4.dtsi:520 */
			status = "disabled";         /* in zephyr/dts/arm/st/l4/stm32l4.dtsi:521 */
			wkup-pins-nb = < 0x5 >;      /* in zephyr/dts/arm/st/l4/stm32l4.dtsi:523 */
			wkup-pins-pol;               /* in zephyr/dts/arm/st/l4/stm32l4.dtsi:524 */
			wkup-pins-pupd;              /* in zephyr/dts/arm/st/l4/stm32l4.dtsi:525 */
			#address-cells = < 0x1 >;    /* in zephyr/dts/arm/st/l4/stm32l4.dtsi:527 */
			#size-cells = < 0x0 >;       /* in zephyr/dts/arm/st/l4/stm32l4.dtsi:528 */

			/* node '/soc/power@40007000/wkup-pin@1' defined in zephyr/dts/arm/st/l4/stm32l4.dtsi:530 */
			wkup-pin@1 {
				reg = < 0x1 >; /* in zephyr/dts/arm/st/l4/stm32l4.dtsi:531 */
			};

			/* node '/soc/power@40007000/wkup-pin@2' defined in zephyr/dts/arm/st/l4/stm32l4.dtsi:534 */
			wkup-pin@2 {
				reg = < 0x2 >; /* in zephyr/dts/arm/st/l4/stm32l4.dtsi:535 */
			};

			/* node '/soc/power@40007000/wkup-pin@3' defined in zephyr/dts/arm/st/l4/stm32l4.dtsi:538 */
			wkup-pin@3 {
				reg = < 0x3 >; /* in zephyr/dts/arm/st/l4/stm32l4.dtsi:539 */
			};

			/* node '/soc/power@40007000/wkup-pin@4' defined in zephyr/dts/arm/st/l4/stm32l4.dtsi:542 */
			wkup-pin@4 {
				reg = < 0x4 >; /* in zephyr/dts/arm/st/l4/stm32l4.dtsi:543 */
			};

			/* node '/soc/power@40007000/wkup-pin@5' defined in zephyr/dts/arm/st/l4/stm32l4.dtsi:546 */
			wkup-pin@5 {
				reg = < 0x5 >; /* in zephyr/dts/arm/st/l4/stm32l4.dtsi:547 */
			};
		};

		/* node '/soc/usb@40006800' defined in zephyr/dts/arm/st/l4/stm32l412.dtsi:27 */
		usb: zephyr_udc0: usb@40006800 {
			compatible = "st,stm32-usb";                             /* in zephyr/dts/arm/st/l4/stm32l412.dtsi:28 */
			reg = < 0x40006800 0x40000 >;                            /* in zephyr/dts/arm/st/l4/stm32l412.dtsi:29 */
			interrupts = < 0x43 0x0 >;                               /* in zephyr/dts/arm/st/l4/stm32l412.dtsi:30 */
			interrupt-names = "usb";                                 /* in zephyr/dts/arm/st/l4/stm32l412.dtsi:31 */
			num-bidir-endpoints = < 0x8 >;                           /* in zephyr/dts/arm/st/l4/stm32l412.dtsi:32 */
			ram-size = < 0x400 >;                                    /* in zephyr/dts/arm/st/l4/stm32l412.dtsi:33 */
			maximum-speed = "full-speed";                            /* in zephyr/dts/arm/st/l4/stm32l412.dtsi:34 */
			phys = < &usb_fs_phy >;                                  /* in zephyr/dts/arm/st/l4/stm32l412.dtsi:35 */
			clocks = < &rcc 0x58 0x4000000 >,
			         < &rcc 0x5 0x3a0088 >;                          /* in zephyr/dts/arm/st/l4/stm32l412.dtsi:36 */
			status = "okay";                                         /* in zephyr/boards/steelseries/apex_pro_mini/apex_pro_mini.dts:231 */
			pinctrl-0 = < &usb_dm_pa11 &usb_dp_pa12 &usb_noe_pa13 >; /* in zephyr/boards/steelseries/apex_pro_mini/apex_pro_mini.dts:232 */
			pinctrl-names = "default";                               /* in zephyr/boards/steelseries/apex_pro_mini/apex_pro_mini.dts:233 */

			/* node '/soc/usb@40006800/cdc_acm_uart0' defined in zephyr/boards/steelseries/apex_pro_mini/apex_pro_mini.dts:235 */
			cdc_acm_uart0: cdc_acm_uart0 {
				compatible = "zephyr,cdc-acm-uart"; /* in zephyr/boards/steelseries/apex_pro_mini/apex_pro_mini.dts:236 */
			};
		};

		/* node '/soc/i2c@40005800' defined in zephyr/dts/arm/st/l4/stm32l412.dtsi:41 */
		i2c2: i2c@40005800 {
			compatible = "st,stm32-i2c-v2";  /* in zephyr/dts/arm/st/l4/stm32l412.dtsi:42 */
			#address-cells = < 0x1 >;        /* in zephyr/dts/arm/st/l4/stm32l412.dtsi:43 */
			#size-cells = < 0x0 >;           /* in zephyr/dts/arm/st/l4/stm32l412.dtsi:44 */
			reg = < 0x40005800 0x400 >;      /* in zephyr/dts/arm/st/l4/stm32l412.dtsi:45 */
			clocks = < &rcc 0x58 0x400000 >; /* in zephyr/dts/arm/st/l4/stm32l412.dtsi:46 */
			clock-frequency = < 0x186a0 >;   /* in zephyr/dts/arm/st/l4/stm32l412.dtsi:47 */
			interrupts = < 0x21 0x0 >,
			             < 0x22 0x0 >;       /* in zephyr/dts/arm/st/l4/stm32l412.dtsi:48 */
			interrupt-names = "event",
			                  "error";       /* in zephyr/dts/arm/st/l4/stm32l412.dtsi:49 */
			status = "disabled";             /* in zephyr/dts/arm/st/l4/stm32l412.dtsi:50 */
			phandle = < 0x1b >;              /* in zephyr/dts/arm/st/l4/stm32l412.dtsi:82 */
		};

		/* node '/soc/spi@40003800' defined in zephyr/dts/arm/st/l4/stm32l412.dtsi:53 */
		spi2: spi@40003800 {
			compatible = "st,stm32-spi-fifo",
			             "st,stm32-spi";                                    /* in zephyr/dts/arm/st/l4/stm32l412.dtsi:54 */
			#address-cells = < 0x1 >;                                       /* in zephyr/dts/arm/st/l4/stm32l412.dtsi:55 */
			#size-cells = < 0x0 >;                                          /* in zephyr/dts/arm/st/l4/stm32l412.dtsi:56 */
			reg = < 0x40003800 0x400 >;                                     /* in zephyr/dts/arm/st/l4/stm32l412.dtsi:57 */
			interrupts = < 0x24 0x5 >;                                      /* in zephyr/dts/arm/st/l4/stm32l412.dtsi:58 */
			clocks = < &rcc 0x58 0x4000 >;                                  /* in zephyr/dts/arm/st/l4/stm32l412.dtsi:59 */
			pinctrl-0 = < &spi2_sck_pb13 &spi2_miso_pb14 &spi2_mosi_pb15 >; /* in zephyr/boards/steelseries/apex_pro_mini/apex_pro_mini.dts:191 */
			pinctrl-names = "default";                                      /* in zephyr/boards/steelseries/apex_pro_mini/apex_pro_mini.dts:192 */
			cs-gpios = < &gpiob 0xc 0x11 >;                                 /* in zephyr/boards/steelseries/apex_pro_mini/apex_pro_mini.dts:193 */
			status = "okay";                                                /* in zephyr/boards/steelseries/apex_pro_mini/apex_pro_mini.dts:194 */
		};

		/* node '/soc/serial@40004800' defined in zephyr/dts/arm/st/l4/stm32l412.dtsi:63 */
		usart3: serial@40004800 {
			compatible = "st,stm32-usart",
			             "st,stm32-uart";   /* in zephyr/dts/arm/st/l4/stm32l412.dtsi:64 */
			reg = < 0x40004800 0x400 >;     /* in zephyr/dts/arm/st/l4/stm32l412.dtsi:65 */
			clocks = < &rcc 0x58 0x40000 >; /* in zephyr/dts/arm/st/l4/stm32l412.dtsi:66 */
			resets = < &rctl 0x712 >;       /* in zephyr/dts/arm/st/l4/stm32l412.dtsi:67 */
			interrupts = < 0x27 0x0 >;      /* in zephyr/dts/arm/st/l4/stm32l412.dtsi:68 */
			status = "disabled";            /* in zephyr/dts/arm/st/l4/stm32l412.dtsi:69 */
		};
	};

	/* node '/cpus' defined in zephyr/dts/arm/st/l4/stm32l4.dtsi:30 */
	cpus {
		#address-cells = < 0x1 >; /* in zephyr/dts/arm/st/l4/stm32l4.dtsi:31 */
		#size-cells = < 0x0 >;    /* in zephyr/dts/arm/st/l4/stm32l4.dtsi:32 */

		/* node '/cpus/cpu@0' defined in zephyr/dts/arm/st/l4/stm32l4.dtsi:34 */
		cpu0: cpu@0 {
			device_type = "cpu";                         /* in zephyr/dts/arm/st/l4/stm32l4.dtsi:35 */
			compatible = "arm,cortex-m4f";               /* in zephyr/dts/arm/st/l4/stm32l4.dtsi:36 */
			reg = < 0x0 >;                               /* in zephyr/dts/arm/st/l4/stm32l4.dtsi:37 */
			cpu-power-states = < &stop0 &stop1 &stop2 >; /* in zephyr/dts/arm/st/l4/stm32l4.dtsi:38 */
		};

		/* node '/cpus/power-states' defined in zephyr/dts/arm/st/l4/stm32l4.dtsi:41 */
		power-states {

			/* node '/cpus/power-states/state0' defined in zephyr/dts/arm/st/l4/stm32l4.dtsi:42 */
			stop0: state0 {
				compatible = "zephyr,power-state";    /* in zephyr/dts/arm/st/l4/stm32l4.dtsi:43 */
				power-state-name = "suspend-to-idle"; /* in zephyr/dts/arm/st/l4/stm32l4.dtsi:44 */
				substate-id = < 0x1 >;                /* in zephyr/dts/arm/st/l4/stm32l4.dtsi:45 */
				min-residency-us = < 0x1f4 >;         /* in zephyr/dts/arm/st/l4/stm32l4.dtsi:46 */
				phandle = < 0x14 >;                   /* in zephyr/dts/arm/st/l4/stm32l4.dtsi:38 */
			};

			/* node '/cpus/power-states/state1' defined in zephyr/dts/arm/st/l4/stm32l4.dtsi:49 */
			stop1: state1 {
				compatible = "zephyr,power-state";    /* in zephyr/dts/arm/st/l4/stm32l4.dtsi:50 */
				power-state-name = "suspend-to-idle"; /* in zephyr/dts/arm/st/l4/stm32l4.dtsi:51 */
				substate-id = < 0x2 >;                /* in zephyr/dts/arm/st/l4/stm32l4.dtsi:52 */
				min-residency-us = < 0x2bc >;         /* in zephyr/dts/arm/st/l4/stm32l4.dtsi:53 */
				phandle = < 0x15 >;                   /* in zephyr/dts/arm/st/l4/stm32l4.dtsi:38 */
			};

			/* node '/cpus/power-states/state2' defined in zephyr/dts/arm/st/l4/stm32l4.dtsi:56 */
			stop2: state2 {
				compatible = "zephyr,power-state";    /* in zephyr/dts/arm/st/l4/stm32l4.dtsi:57 */
				power-state-name = "suspend-to-idle"; /* in zephyr/dts/arm/st/l4/stm32l4.dtsi:58 */
				substate-id = < 0x3 >;                /* in zephyr/dts/arm/st/l4/stm32l4.dtsi:59 */
				min-residency-us = < 0x3e8 >;         /* in zephyr/dts/arm/st/l4/stm32l4.dtsi:60 */
				phandle = < 0x16 >;                   /* in zephyr/dts/arm/st/l4/stm32l4.dtsi:38 */
			};
		};
	};

	/* node '/memory@20000000' defined in zephyr/dts/arm/st/l4/stm32l4.dtsi:65 */
	sram0: memory@20000000 {
		compatible = "zephyr,memory-region",
		             "mmio-sram";            /* in zephyr/dts/arm/st/l4/stm32l4.dtsi:66 */
		zephyr,memory-region = "SRAM0";      /* in zephyr/dts/arm/st/l4/stm32l4.dtsi:67 */
		reg = < 0x20000000 0xa000 >;         /* in zephyr/dts/arm/st/l4/stm32l412XB.dtsi:11 */
	};

	/* node '/clocks' defined in zephyr/dts/arm/st/l4/stm32l4.dtsi:70 */
	clocks {

		/* node '/clocks/clk-hse' defined in zephyr/dts/arm/st/l4/stm32l4.dtsi:71 */
		clk_hse: clk-hse {
			#clock-cells = < 0x0 >;            /* in zephyr/dts/arm/st/l4/stm32l4.dtsi:72 */
			compatible = "st,stm32-hse-clock"; /* in zephyr/dts/arm/st/l4/stm32l4.dtsi:73 */
			status = "disabled";               /* in zephyr/dts/arm/st/l4/stm32l4.dtsi:74 */
		};

		/* node '/clocks/clk-hsi' defined in zephyr/dts/arm/st/l4/stm32l4.dtsi:77 */
		clk_hsi: clk-hsi {
			#clock-cells = < 0x0 >;         /* in zephyr/dts/arm/st/l4/stm32l4.dtsi:78 */
			compatible = "fixed-clock";     /* in zephyr/dts/arm/st/l4/stm32l4.dtsi:79 */
			clock-frequency = < 0xf42400 >; /* in zephyr/dts/arm/st/l4/stm32l4.dtsi:80 */
			status = "okay";                /* in zephyr/boards/steelseries/apex_pro_mini/apex_pro_mini.dts:143 */
			phandle = < 0x17 >;             /* in zephyr/boards/steelseries/apex_pro_mini/apex_pro_mini.dts:155 */
		};

		/* node '/clocks/clk-msi' defined in zephyr/dts/arm/st/l4/stm32l4.dtsi:84 */
		clk_msi: clk-msi {
			#clock-cells = < 0x0 >;            /* in zephyr/dts/arm/st/l4/stm32l4.dtsi:85 */
			compatible = "st,stm32-msi-clock"; /* in zephyr/dts/arm/st/l4/stm32l4.dtsi:86 */
			msi-range = < 0x6 >;               /* in zephyr/dts/arm/st/l4/stm32l4.dtsi:87 */
			status = "disabled";               /* in zephyr/dts/arm/st/l4/stm32l4.dtsi:88 */
		};

		/* node '/clocks/clk-lse' defined in zephyr/dts/arm/st/l4/stm32l4.dtsi:91 */
		clk_lse: clk-lse {
			#clock-cells = < 0x0 >;            /* in zephyr/dts/arm/st/l4/stm32l4.dtsi:92 */
			compatible = "st,stm32-lse-clock"; /* in zephyr/dts/arm/st/l4/stm32l4.dtsi:93 */
			clock-frequency = < 0x8000 >;      /* in zephyr/dts/arm/st/l4/stm32l4.dtsi:94 */
			driving-capability = < 0x0 >;      /* in zephyr/dts/arm/st/l4/stm32l4.dtsi:95 */
			status = "disabled";               /* in zephyr/dts/arm/st/l4/stm32l4.dtsi:96 */
		};

		/* node '/clocks/clk-lsi' defined in zephyr/dts/arm/st/l4/stm32l4.dtsi:99 */
		clk_lsi: clk-lsi {
			#clock-cells = < 0x0 >;       /* in zephyr/dts/arm/st/l4/stm32l4.dtsi:100 */
			compatible = "fixed-clock";   /* in zephyr/dts/arm/st/l4/stm32l4.dtsi:101 */
			clock-frequency = < 0x7d00 >; /* in zephyr/dts/arm/st/l4/stm32l4.dtsi:102 */
			status = "okay";              /* in zephyr/boards/steelseries/apex_pro_mini/apex_pro_mini.dts:139 */
		};

		/* node '/clocks/pll' defined in zephyr/dts/arm/st/l4/stm32l4.dtsi:106 */
		pll: pll {
			#clock-cells = < 0x0 >;              /* in zephyr/dts/arm/st/l4/stm32l4.dtsi:107 */
			compatible = "st,stm32l4-pll-clock"; /* in zephyr/dts/arm/st/l4/stm32l4.dtsi:108 */
			div-m = < 0x1 >;                     /* in zephyr/boards/steelseries/apex_pro_mini/apex_pro_mini.dts:151 */
			mul-n = < 0xa >;                     /* in zephyr/boards/steelseries/apex_pro_mini/apex_pro_mini.dts:152 */
			div-q = < 0x2 >;                     /* in zephyr/boards/steelseries/apex_pro_mini/apex_pro_mini.dts:153 */
			div-r = < 0x2 >;                     /* in zephyr/boards/steelseries/apex_pro_mini/apex_pro_mini.dts:154 */
			clocks = < &clk_hsi >;               /* in zephyr/boards/steelseries/apex_pro_mini/apex_pro_mini.dts:155 */
			status = "okay";                     /* in zephyr/boards/steelseries/apex_pro_mini/apex_pro_mini.dts:156 */
			phandle = < 0x3 >;                   /* in zephyr/boards/steelseries/apex_pro_mini/apex_pro_mini.dts:160 */
		};

		/* node '/clocks/pllsai1' defined in zephyr/dts/arm/st/l4/stm32l4.dtsi:112 */
		pllsai1: pllsai1 {
			#clock-cells = < 0x0 >;                 /* in zephyr/dts/arm/st/l4/stm32l4.dtsi:113 */
			compatible = "st,stm32l4-pllsai-clock"; /* in zephyr/dts/arm/st/l4/stm32l4.dtsi:114 */
			status = "disabled";                    /* in zephyr/dts/arm/st/l4/stm32l4.dtsi:115 */
		};

		/* node '/clocks/clk-hsi48' defined in zephyr/dts/arm/st/l4/stm32l412.dtsi:11 */
		clk_hsi48: clk-hsi48 {
			#clock-cells = < 0x0 >;          /* in zephyr/dts/arm/st/l4/stm32l412.dtsi:12 */
			compatible = "fixed-clock";      /* in zephyr/dts/arm/st/l4/stm32l412.dtsi:13 */
			clock-frequency = < 0x2dc6c00 >; /* in zephyr/dts/arm/st/l4/stm32l412.dtsi:14 */
			status = "okay";                 /* in zephyr/boards/steelseries/apex_pro_mini/apex_pro_mini.dts:147 */
		};
	};

	/* node '/mcos' defined in zephyr/dts/arm/st/l4/stm32l4.dtsi:119 */
	mcos {

		/* node '/mcos/mco1' defined in zephyr/dts/arm/st/l4/stm32l4.dtsi:120 */
		mco1: mco1 {
			compatible = "st,stm32-clock-mco"; /* in zephyr/dts/arm/st/l4/stm32l4.dtsi:121 */
			status = "disabled";               /* in zephyr/dts/arm/st/l4/stm32l4.dtsi:122 */
		};
	};

	/* node '/dietemp' defined in zephyr/dts/arm/st/l4/stm32l4.dtsi:552 */
	die_temp: dietemp {
		compatible = "st,stm32-temp-cal"; /* in zephyr/dts/arm/st/l4/stm32l4.dtsi:553 */
		ts-cal1-addr = < 0x1fff75a8 >;    /* in zephyr/dts/arm/st/l4/stm32l4.dtsi:554 */
		ts-cal2-addr = < 0x1fff75ca >;    /* in zephyr/dts/arm/st/l4/stm32l4.dtsi:555 */
		ts-cal1-temp = < 0x1e >;          /* in zephyr/dts/arm/st/l4/stm32l4.dtsi:556 */
		ts-cal2-temp = < 0x82 >;          /* in zephyr/dts/arm/st/l4/stm32l4.dtsi:557 */
		ts-cal-vrefanalog = < 0xbb8 >;    /* in zephyr/dts/arm/st/l4/stm32l4.dtsi:558 */
		io-channels = < &adc1 0x11 >;     /* in zephyr/dts/arm/st/l4/stm32l4.dtsi:559 */
		status = "disabled";              /* in zephyr/dts/arm/st/l4/stm32l4.dtsi:560 */
	};

	/* node '/vref' defined in zephyr/dts/arm/st/l4/stm32l4.dtsi:563 */
	vref: vref {
		compatible = "st,stm32-vref";      /* in zephyr/dts/arm/st/l4/stm32l4.dtsi:564 */
		vrefint-cal-addr = < 0x1fff75aa >; /* in zephyr/dts/arm/st/l4/stm32l4.dtsi:565 */
		vrefint-cal-mv = < 0xbb8 >;        /* in zephyr/dts/arm/st/l4/stm32l4.dtsi:566 */
		io-channels = < &adc1 0x0 >;       /* in zephyr/dts/arm/st/l4/stm32l4.dtsi:567 */
		status = "okay";                   /* in zephyr/boards/steelseries/apex_pro_mini/apex_pro_mini.dts:241 */
	};

	/* node '/vbat' defined in zephyr/dts/arm/st/l4/stm32l4.dtsi:571 */
	vbat: vbat {
		compatible = "st,stm32-vbat"; /* in zephyr/dts/arm/st/l4/stm32l4.dtsi:572 */
		ratio = < 0x3 >;              /* in zephyr/dts/arm/st/l4/stm32l4.dtsi:573 */
		io-channels = < &adc1 0x12 >; /* in zephyr/dts/arm/st/l4/stm32l4.dtsi:574 */
		status = "okay";              /* in zephyr/boards/steelseries/apex_pro_mini/apex_pro_mini.dts:245 */
	};

	/* node '/smbus1' defined in zephyr/dts/arm/st/l4/stm32l4.dtsi:578 */
	smbus1: smbus1 {
		compatible = "st,stm32-smbus"; /* in zephyr/dts/arm/st/l4/stm32l4.dtsi:579 */
		#address-cells = < 0x1 >;      /* in zephyr/dts/arm/st/l4/stm32l4.dtsi:580 */
		#size-cells = < 0x0 >;         /* in zephyr/dts/arm/st/l4/stm32l4.dtsi:581 */
		i2c = < &i2c1 >;               /* in zephyr/dts/arm/st/l4/stm32l4.dtsi:582 */
		status = "disabled";           /* in zephyr/dts/arm/st/l4/stm32l4.dtsi:583 */
	};

	/* node '/smbus3' defined in zephyr/dts/arm/st/l4/stm32l4.dtsi:586 */
	smbus3: smbus3 {
		compatible = "st,stm32-smbus"; /* in zephyr/dts/arm/st/l4/stm32l4.dtsi:587 */
		#address-cells = < 0x1 >;      /* in zephyr/dts/arm/st/l4/stm32l4.dtsi:588 */
		#size-cells = < 0x0 >;         /* in zephyr/dts/arm/st/l4/stm32l4.dtsi:589 */
		i2c = < &i2c3 >;               /* in zephyr/dts/arm/st/l4/stm32l4.dtsi:590 */
		status = "disabled";           /* in zephyr/dts/arm/st/l4/stm32l4.dtsi:591 */
	};

	/* node '/usbphy' defined in zephyr/dts/arm/st/l4/stm32l412.dtsi:73 */
	usb_fs_phy: usbphy {
		compatible = "usb-nop-xceiv"; /* in zephyr/dts/arm/st/l4/stm32l412.dtsi:74 */
		#phy-cells = < 0x0 >;         /* in zephyr/dts/arm/st/l4/stm32l412.dtsi:75 */
		status = "okay";              /* in zephyr/boards/steelseries/apex_pro_mini/apex_pro_mini.dts:227 */
		phandle = < 0xc >;            /* in zephyr/dts/arm/st/l4/stm32l412.dtsi:35 */
	};

	/* node '/smbus2' defined in zephyr/dts/arm/st/l4/stm32l412.dtsi:78 */
	smbus2: smbus2 {
		compatible = "st,stm32-smbus"; /* in zephyr/dts/arm/st/l4/stm32l412.dtsi:79 */
		#address-cells = < 0x1 >;      /* in zephyr/dts/arm/st/l4/stm32l412.dtsi:80 */
		#size-cells = < 0x0 >;         /* in zephyr/dts/arm/st/l4/stm32l412.dtsi:81 */
		i2c = < &i2c2 >;               /* in zephyr/dts/arm/st/l4/stm32l412.dtsi:82 */
		status = "disabled";           /* in zephyr/dts/arm/st/l4/stm32l412.dtsi:83 */
	};

	/* node '/leds' defined in zephyr/boards/steelseries/apex_pro_mini/apex_pro_mini.dts:24 */
	leds: leds {
		compatible = "gpio-leds"; /* in zephyr/boards/steelseries/apex_pro_mini/apex_pro_mini.dts:25 */

		/* node '/leds/led_0' defined in zephyr/boards/steelseries/apex_pro_mini/apex_pro_mini.dts:27 */
		dbg_led: led_0 {
			gpios = < &gpioc 0xc 0x0 >; /* in zephyr/boards/steelseries/apex_pro_mini/apex_pro_mini.dts:28 */
			label = "User dbg tp";      /* in zephyr/boards/steelseries/apex_pro_mini/apex_pro_mini.dts:29 */
		};
	};

	/* node '/kbd-matrix' defined in zephyr/boards/steelseries/apex_pro_mini/apex_pro_mini.dts:39 */
	kbd: kbd-matrix {
		compatible = "gpio-kbd-matrix";  /* in zephyr/boards/steelseries/apex_pro_mini/apex_pro_mini.dts:40 */
		status = "okay";                 /* in zephyr/boards/steelseries/apex_pro_mini/apex_pro_mini.dts:41 */
		idle-mode = "poll";              /* in zephyr/boards/steelseries/apex_pro_mini/apex_pro_mini.dts:42 */
		settle-time-us = < 0x6e >;       /* in zephyr/boards/steelseries/apex_pro_mini/apex_pro_mini.dts:43 */
		no-ghostkey-check;               /* in zephyr/boards/steelseries/apex_pro_mini/apex_pro_mini.dts:44 */
		col-drive-inactive;              /* in zephyr/boards/steelseries/apex_pro_mini/apex_pro_mini.dts:45 */
		col-gpios = < &gpiob 0x0 0x20 >,
		            < &gpiob 0x1 0x20 >,
		            < &gpiob 0x2 0x20 >,
		            < &gpiob 0xa 0x20 >,
		            < &gpiob 0xb 0x20 >; /* in zephyr/boards/steelseries/apex_pro_mini/apex_pro_mini.dts:46 */
		row-gpios = < &gpioa 0x0 0x0 >,
		            < &gpioa 0x1 0x0 >,
		            < &gpioa 0x2 0x0 >,
		            < &gpioa 0x3 0x0 >,
		            < &gpioa 0x4 0x0 >,
		            < &gpioa 0x5 0x0 >,
		            < &gpioa 0x6 0x0 >,
		            < &gpioa 0x7 0x0 >,
		            < &gpioc 0x4 0x0 >,
		            < &gpioc 0x5 0x0 >,
		            < &gpioc 0x0 0x0 >,
		            < &gpioc 0x1 0x0 >,
		            < &gpioc 0x2 0x0 >,
		            < &gpioc 0x3 0x0 >;  /* in zephyr/boards/steelseries/apex_pro_mini/apex_pro_mini.dts:52 */

		/* node '/kbd-matrix/keymap' defined in zephyr/boards/steelseries/apex_pro_mini/apex_pro_mini.dts:68 */
		keymap {
			compatible = "input-keymap";                                                                         /* in zephyr/boards/steelseries/apex_pro_mini/apex_pro_mini.dts:69 */
			row-size = < 0xe >;                                                                                  /* in zephyr/boards/steelseries/apex_pro_mini/apex_pro_mini.dts:70 */
			col-size = < 0x5 >;                                                                                  /* in zephyr/boards/steelseries/apex_pro_mini/apex_pro_mini.dts:71 */
			keymap = < 0x1 0x1000002 0x2000003 0x3000004 0x4000005 0x5000006 0x6000007 0x7000008 0x8000009
			           0x900000a 0xa00000b 0xb00000c 0xc00000d 0xd00000e 0x1000f 0x101001e 0x201002c 0x3010012
			           0x4010013 0x5010014 0x6010015 0x7010016 0x8010017 0x9010018 0xa010019 0xb01001a 0xc01001b
			           0x2003a 0x1020010 0x202001f 0x3020020 0x4020021 0x5020022 0x6020023 0x7020024 0x8020025
			           0x9020026 0xa020032 0xb020027 0xc02002b 0xd02001c 0x3002a 0x1030066 0x2030011 0x303002d
			           0x403002e 0x503002f 0x6030030 0x7030031 0x8030032 0x9030033 0xa030034 0xb030035 0xd030036
			           0x4001d 0x104007d 0x2040038 0x4040039 0x7040064 0x804007e 0x9040098 0xa040061 >;          /* in zephyr/boards/steelseries/apex_pro_mini/apex_pro_mini.dts:72 */
		};
	};
};
